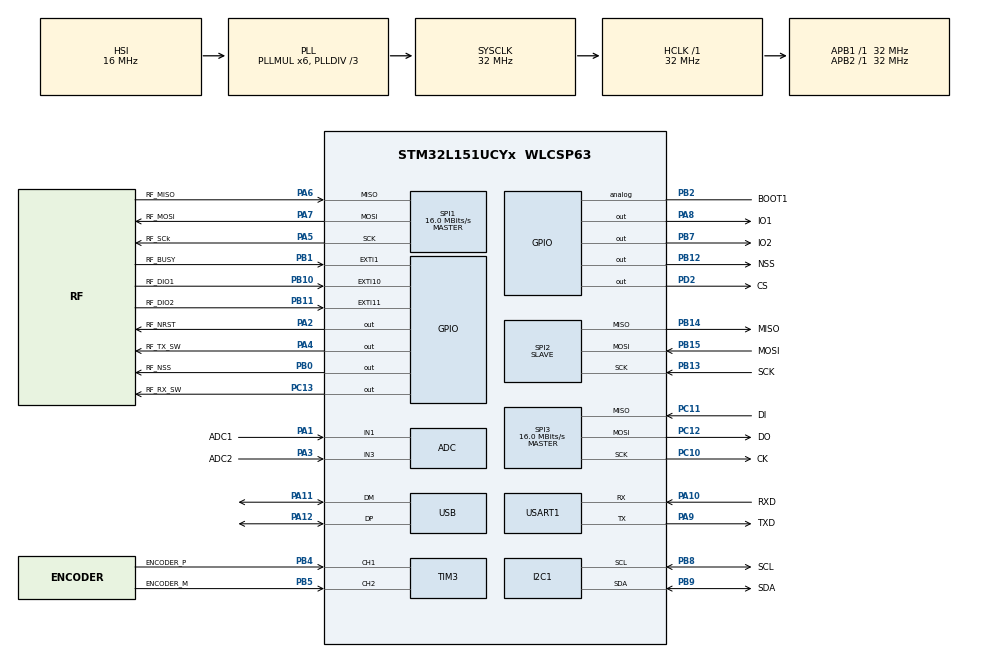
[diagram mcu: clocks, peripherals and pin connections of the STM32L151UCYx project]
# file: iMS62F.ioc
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ADC.Channel-0\#ChannelRegularConversion=ADC_CHANNEL_TEMPSENSOR
ADC.NbrOfConversionFlag=1
ADC.Rank-0\#ChannelRegularConversion=1
ADC.SamplingTime-0\#ChannelRegularConversion=ADC_SAMPLETIME_4CYCLES
IWDG.Prescaler=IWDG_PRESCALER_256
Mcu.Family=STM32L1
Mcu.Name=STM32L151UCYx
Mcu.Package=WLCSP63
NVIC.ADC1_IRQn=true\:0\:0\:false\:false\:true\:true\:true\:true
NVIC.EXTI15_10_IRQn=true\:0\:0\:false\:false\:true\:true\:true\:true
NVIC.EXTI1_IRQn=true\:0\:0\:false\:false\:true\:true\:true\:true
NVIC.FLASH_IRQn=true\:0\:0\:false\:false\:true\:true\:true\:true
NVIC.I2C1_ER_IRQn=true\:0\:0\:false\:false\:true\:true\:true\:true
NVIC.I2C1_EV_IRQn=true\:0\:0\:false\:false\:true\:true\:true\:true
NVIC.PVD_IRQn=true\:0\:0\:false\:false\:true\:true\:true\:true
NVIC.PriorityGroup=NVIC_PRIORITYGROUP_4
NVIC.RCC_IRQn=true\:0\:0\:false\:false\:true\:true\:false\:true
NVIC.SPI1_IRQn=true\:0\:0\:false\:false\:true\:true\:true\:true
NVIC.SPI2_IRQn=true\:0\:0\:false\:false\:true\:true\:true\:true
NVIC.SPI3_IRQn=true\:0\:0\:false\:false\:true\:true\:true\:true
NVIC.TIM2_IRQn=true\:0\:0\:false\:false\:true\:true\:true\:true
NVIC.TIM3_IRQn=true\:0\:0\:false\:false\:true\:true\:true\:true
NVIC.TIM4_IRQn=true\:0\:0\:false\:false\:true\:true\:true\:true
NVIC.TIM6_IRQn=true\:15\:0\:false\:false\:true\:false\:true\:true
NVIC.TimeBase=TIM6_IRQn
NVIC.TimeBaseIP=TIM6
NVIC.USART1_IRQn=true\:0\:0\:false\:false\:true\:true\:true\:true
NVIC.USB_HP_IRQn=true\:0\:0\:false\:false\:true\:true\:true\:true
NVIC.USB_LP_IRQn=true\:0\:0\:false\:false\:true\:true\:true\:true
NVIC.WWDG_IRQn=true\:0\:0\:false\:false\:true\:true\:true\:true
PA0-WKUP1.GPIO_Label=WKUP
PA0-WKUP1.Mode=SYS_WakeUp0
PA0-WKUP1.Signal=SYS_WKUP1
PA1.GPIO_Label=ADC1
PA1.Signal=SharedStack_PA1
PA1.Stacked=true
PA10.GPIO_Label=RXD
PA10.Mode=Asynchronous
PA10.Signal=USART1_RX
PA11.Mode=Device
PA11.Signal=USB_DM
PA12.Mode=Device
PA12.Signal=USB_DP
PA13.Mode=Trace_Asynchronous_SW
PA13.Signal=SYS_JTMS-SWDIO
PA14.Mode=Trace_Asynchronous_SW
PA14.Signal=SYS_JTCK-SWCLK
PA15.Signal=TS_G5_IO3
PA2.GPIO_Label=RF_NRST
PA2.Signal=GPIO_Output
PA3.GPIO_Label=ADC2
PA3.Signal=SharedStack_PA3
PA3.Stacked=true
PA4.GPIO_Label=RF_TX_SW
PA4.Signal=GPIO_Output
PA5.GPIO_Label=RF_SCk
PA5.Mode=Full_Duplex_Master
PA5.Signal=SPI1_SCK
PA6.GPIO_Label=RF_MISO
PA6.Mode=Full_Duplex_Master
PA6.Signal=SPI1_MISO
PA7.GPIO_Label=RF_MOSI
PA7.Mode=Full_Duplex_Master
PA7.Signal=SPI1_MOSI
PA8.GPIO_Label=IO1
PA8.Signal=GPIO_Output
PA9.GPIO_Label=TXD
PA9.Mode=Asynchronous
PA9.Signal=USART1_TX
PB0.GPIO_Label=RF_NSS
PB0.Signal=GPIO_Output
PB1.GPIO_Label=RF_BUSY
PB1.Signal=GPXTI1
PB10.GPIO_Label=RF_DIO1
PB10.Signal=GPXTI10
PB11.GPIO_Label=RF_DIO2
PB11.Signal=GPXTI11
PB12.GPIO_Label=NSS
PB12.Signal=GPIO_Output
PB13.GPIO_Label=SCK
PB13.Mode=Full_Duplex_Slave
PB13.Signal=SPI2_SCK
PB14.GPIO_Label=MISO
PB14.Mode=Full_Duplex_Slave
PB14.Signal=SPI2_MISO
PB15.GPIO_Label=MOSI
PB15.Mode=Full_Duplex_Slave
PB15.Signal=SPI2_MOSI
PB2.GPIO_Label=BOOT1
PB2.Signal=GPIO_Analog
PB3.Mode=Trace_Asynchronous_SW
PB3.Signal=SYS_JTDO-TRACESWO
PB4.GPIO_Label=ENCODER_P
PB4.Signal=S_TIM3_CH1
PB5.GPIO_Label=ENCODER_M
PB5.Signal=S_TIM3_CH2
PB7.GPIO_Label=IO2
PB7.Signal=GPIO_Output
PB8.GPIO_Label=SCL
PB8.Mode=I2C
PB8.Signal=I2C1_SCL
PB9.GPIO_Label=SDA
PB9.Mode=I2C
PB9.Signal=I2C1_SDA
PC10.GPIO_Label=CK
PC10.Mode=Full_Duplex_Master
PC10.Signal=SPI3_SCK
PC11.GPIO_Label=DI
PC11.Mode=Full_Duplex_Master
PC11.Signal=SPI3_MISO
PC12.GPIO_Label=DO
PC12.Mode=Full_Duplex_Master
PC12.Signal=SPI3_MOSI
PC13-WKUP2.GPIO_Label=RF_RX_SW
PC13-WKUP2.Signal=GPIO_Output
PC14-OSC32_IN.Mode=LSE-External-Oscillator
PC14-OSC32_IN.Signal=RCC_OSC32_IN
PC15-OSC32_OUT.Mode=LSE-External-Oscillator
PC15-OSC32_OUT.Signal=RCC_OSC32_OUT
PC4.Signal=TIMX_IC1
PD2.GPIO_Label=CS
PD2.Signal=GPIO_Output
PH0-OSC_IN.Mode=HSE-External-Oscillator
PH0-OSC_IN.Signal=RCC_OSC_IN
PH1-OSC_OUT.Mode=HSE-External-Oscillator
PH1-OSC_OUT.Signal=RCC_OSC_OUT
ProjectManager.HeapSize=0x200
ProjectManager.StackSize=0x400
ProjectManager.TargetToolchain=STM32CubeIDE
RCC.48MHZClocksFreq_Value=48000000
RCC.AHBFreq_Value=32000000
RCC.APB1Freq_Value=32000000
RCC.APB1TimFreq_Value=32000000
RCC.APB2Freq_Value=32000000
RCC.APB2TimFreq_Value=32000000
RCC.EnableCSSLSE=true
RCC.EnbaleCSS=true
RCC.HCLKFreq_Value=32000000
RCC.HSE_VALUE=8000000
RCC.HSI_VALUE=16000000
RCC.MSIClockRange=RCC_MSIRANGE_6
RCC.MSI_VALUE=4194000
RCC.PLLDIV=RCC_PLL_DIV3
RCC.PLLMUL=RCC_PLL_MUL12
RCC.RTCClockSelectionVirtual=RCC_RTCCLKSOURCE_LSE
RCC.SYSCLKFreq_VALUE=32000000
RCC.SYSCLKSource=RCC_SYSCLKSOURCE_PLLCLK
RCC.VCOOutputFreq_Value=96000000
SH.S_TIM3_CH1.0=TIM3_CH1,Encoder_Interface
SH.S_TIM3_CH2.0=TIM3_CH2,Encoder_Interface
SH.SharedStack_PA1.0=ADC_IN1,IN1
SH.SharedStack_PA1.1=TS_G1_IO2
SH.SharedStack_PA3.0=ADC_IN3,IN3
SH.SharedStack_PA3.1=TS_G1_IO4
SPI1.BaudRatePrescaler=SPI_BAUDRATEPRESCALER_2
SPI1.CalculateBaudRate=16.0 MBits/s
SPI1.Direction=SPI_DIRECTION_2LINES
SPI1.Mode=SPI_MODE_MASTER
SPI1.VirtualType=VM_MASTER
SPI2.Direction=SPI_DIRECTION_2LINES
SPI2.Mode=SPI_MODE_SLAVE
SPI2.VirtualType=VM_SLAVE
SPI3.BaudRatePrescaler=SPI_BAUDRATEPRESCALER_2
SPI3.CalculateBaudRate=16.0 MBits/s
SPI3.Direction=SPI_DIRECTION_2LINES
SPI3.Mode=SPI_MODE_MASTER
SPI3.VirtualType=VM_MASTER
USART1.VirtualMode=VM_ASYNC
USB_DEVICE.CLASS_NAME_FS=DFU
USB_DEVICE.VirtualMode=Dfu
USB_DEVICE.VirtualModeFS=Dfu_FS
VP_ADC_TempSens_Input.Mode=IN-TempSens
VP_ADC_Vref_Input.Mode=IN-Vrefint
VP_CRC_VS_CRC.Mode=CRC_Activate
VP_IWDG_VS_IWDG.Mode=IWDG_Activate
VP_RTC_VS_RTC_Activate.Mode=RTC_Enabled
VP_RTC_VS_RTC_Calendar.Mode=RTC_Calendar
VP_SYS_VS_tim6.Mode=TIM6
VP_SYS_V_PVD_IN.Mode=Mode_PVD_Int
VP_TIM2_VS_ClockSourceINT.Mode=Internal
VP_TIM4_VS_ClockSourceINT.Mode=Internal
VP_USB_DEVICE_VS_USB_DEVICE_DFU_FS.Mode=DFU_FS
VP_WWDG_VS_WWDG.Mode=WWDG_Activate
WWDG.EWIMode=WWDG_EWI_ENABLE
WWDG.Prescaler=WWDG_PRESCALER_8
board=custom

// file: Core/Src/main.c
/* USER CODE BEGIN Header */
/**
  ******************************************************************************
  * @file           : main.c
  * @brief          : Main program body
  ******************************************************************************
  * @attention
  *
  * Copyright (c) 2022 STMicroelectronics.
  * All rights reserved.
  *
  * This software is licensed under terms that can be found in the LICENSE file
  * in the root directory of this software component.
  * If no LICENSE file comes with this software, it is provided AS-IS.
  *
  ******************************************************************************
  */
/* USER CODE END Header */
#include <emod_adc.h>
#include <emod_crc.h>
#include <emod_gpio.h>
#include <emod_i2c.h>
#include <emod_iwdg.h>
#include <emod_rtc.h>
#include <emod_spi.h>
#include <emod_tim.h>
#include <emod_uart.h>
#include <emod_usart.h>
#include <emod_wwdg.h>
#include "main.h"
#include "usb_device.h"
#include "WiMODLRHCI.h"
#include "WiMODLoRaWAN.h"
/* USER CODE END Includes */

/* USER CODE BEGIN PV */
__IO uint8_t Rx2_byte = 0x00;

const char NWKSKEY[16] = { 0x01, 0x02, 0x03, 0x04, 0x05, 0x06, 0x07, 0x08, 0x09, 0x0A, 0x0B, 0x0C, 0x0D, 0x0E, 0x0f, 0x10 };
const char APPSKEY[16] = { 0x01, 0x02, 0x03, 0x04, 0x05, 0x06, 0x07, 0x08, 0x09, 0x0A, 0x0B, 0x0C, 0x0D, 0x0E, 0x0f, 0x10 };
 // create a local variable
TWiMODLORAWAN_ActivateDeviceData activationData;
/* USER CODE END PV */

void SystemClock_Config(void);

int main(void)
{

  /* MCU Configuration--------------------------------------------------------*/

  /* Reset of all peripherals, Initializes the Flash interface and the Systick. */
  HAL_Init();

  /* Configure the system clock */
  SystemClock_Config();

  /* Initialize all configured peripherals */
  MX_GPIO_Init();
  MX_CRC_Init();
  MX_I2C1_Init();
  MX_RTC_Init();
  MX_SPI1_Init();
  MX_SPI2_Init();
  MX_SPI3_Init();
  MX_USART1_UART_Init();
  MX_ADC_Init();
//  MX_IWDG_Init();
//  MX_WWDG_Init();
//  MX_USB_DEVICE_Init();
  MX_TIM2_Init();
  MX_TIM3_Init();
  MX_TIM4_Init();
  /* USER CODE BEGIN 2 */
  HAL_UART_Receive_IT(&huart1, (uint8_t*) &Rx2_byte, 1);

    TWiMODLRHCI.begin(&huart1);
    WiMODLoRaWAN.beginAndAutoSetup();
  //  WiMODLoRaWAN.PrintBasicDeviceInfo(&Serial);
    //setup data
    activationData.DeviceAddress = WIMOD_DEV_ADDR;
    memcpy(activationData.NwkSKey, NWKSKEY, 16);
    memcpy(activationData.AppSKey, APPSKEY, 16);

    HAL_TIM_Base_Start_IT(&htim2);
    HAL_TIM_Base_Start_IT(&htim4);
//    HAL_TIM_Base_Start_IT(&htim8);
  /* USER CODE END 2 */

  /* Infinite loop */
  /* USER CODE BEGIN WHILE */
  while (1)
  {
//	  HAL_UART_Transmit(&huart1, "test\n", 5, 1000);
    /* USER CODE END WHILE */

    /* USER CODE BEGIN 3 */
	  __NOP();
  }
  /* USER CODE END 3 */
}

void SystemClock_Config(void)
{
  RCC_OscInitTypeDef RCC_OscInitStruct = {0};
  RCC_ClkInitTypeDef RCC_ClkInitStruct = {0};
  RCC_PeriphCLKInitTypeDef PeriphClkInit = {0};

  /** Configure the main internal regulator output voltage
  */
  __HAL_PWR_VOLTAGESCALING_CONFIG(PWR_REGULATOR_VOLTAGE_SCALE1);
  /** Initializes the RCC Oscillators according to the specified parameters
  * in the RCC_OscInitTypeDef structure.
  */
  RCC_OscInitStruct.OscillatorType = RCC_OSCILLATORTYPE_HSI|RCC_OSCILLATORTYPE_LSI;
  RCC_OscInitStruct.HSIState = RCC_HSI_ON;
  RCC_OscInitStruct.HSICalibrationValue = RCC_HSICALIBRATION_DEFAULT;
  RCC_OscInitStruct.LSIState = RCC_LSI_ON;
  RCC_OscInitStruct.PLL.PLLState = RCC_PLL_ON;
  RCC_OscInitStruct.PLL.PLLSource = RCC_PLLSOURCE_HSI;
  RCC_OscInitStruct.PLL.PLLMUL = RCC_PLL_MUL6;
  RCC_OscInitStruct.PLL.PLLDIV = RCC_PLL_DIV3;
  if (HAL_RCC_OscConfig(&RCC_OscInitStruct) != HAL_OK)
  {
    Error_Handler();
  }
  /** Initializes the CPU, AHB and APB buses clocks
  */
  RCC_ClkInitStruct.ClockType = RCC_CLOCKTYPE_HCLK|RCC_CLOCKTYPE_SYSCLK
                              |RCC_CLOCKTYPE_PCLK1|RCC_CLOCKTYPE_PCLK2;
  RCC_ClkInitStruct.SYSCLKSource = RCC_SYSCLKSOURCE_PLLCLK;
  RCC_ClkInitStruct.AHBCLKDivider = RCC_SYSCLK_DIV1;
  RCC_ClkInitStruct.APB1CLKDivider = RCC_HCLK_DIV1;
  RCC_ClkInitStruct.APB2CLKDivider = RCC_HCLK_DIV1;

  if (HAL_RCC_ClockConfig(&RCC_ClkInitStruct, FLASH_LATENCY_1) != HAL_OK)
  {
    Error_Handler();
  }
  PeriphClkInit.PeriphClockSelection = RCC_PERIPHCLK_RTC;
  PeriphClkInit.RTCClockSelection = RCC_RTCCLKSOURCE_LSI;
  if (HAL_RCCEx_PeriphCLKConfig(&PeriphClkInit) != HAL_OK)
  {
    Error_Handler();
  }
}

void HAL_TIM_PeriodElapsedCallback(TIM_HandleTypeDef *htim)
{
  if (htim->Instance == TIM6) {
    HAL_IncTick();
  }
}

void Error_Handler(void)
{
  __disable_irq();
  while (1)
  {
  }
}
